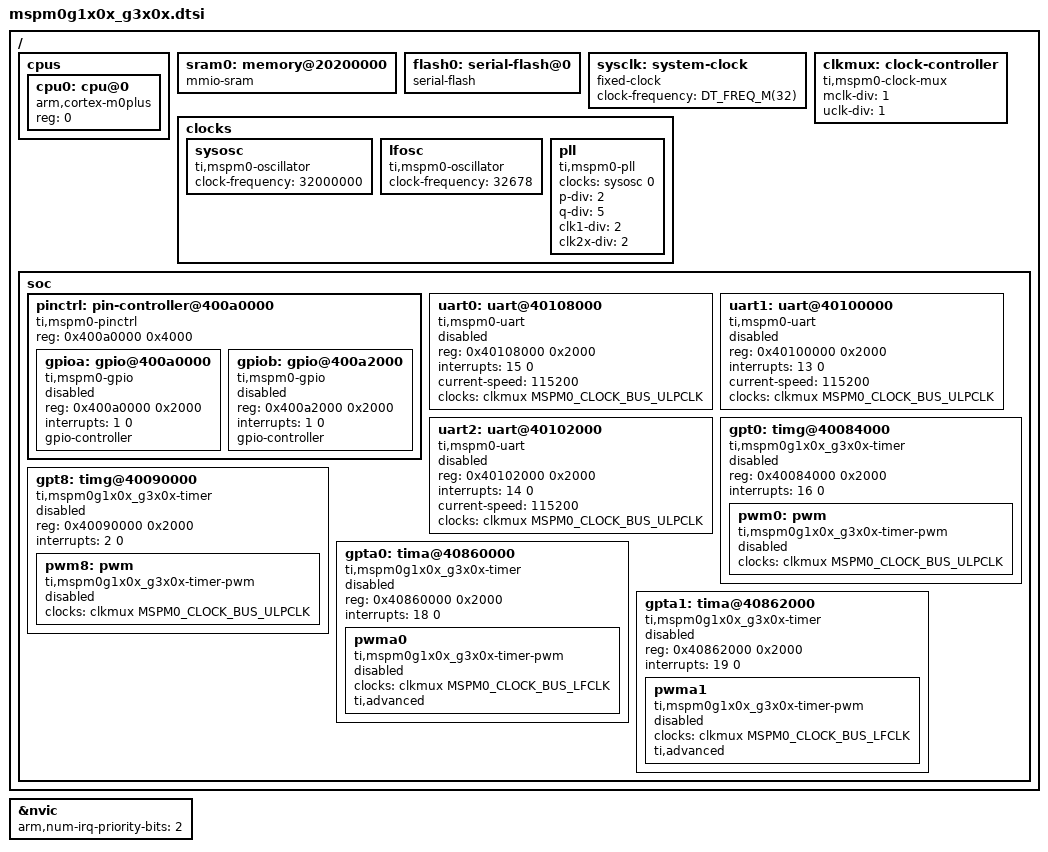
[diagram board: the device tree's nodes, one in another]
/* SPDX-License-Identifier: Apache-2.0 */

#include <arm/armv6-m.dtsi>
#include <zephyr/dt-bindings/gpio/gpio.h>
#include <zephyr/dt-bindings/i2c/i2c.h>
#include <zephyr/dt-bindings/clock/mspm0_clock.h>
#include <freq.h>

/ {
	cpus {
		#address-cells = <1>;
		#size-cells = <0>;

		cpu0: cpu@0 {
			compatible = "arm,cortex-m0plus";
			reg = <0>;
		};
	};

	sram0: memory@20200000 {
		compatible = "mmio-sram";
	};

	flash0: serial-flash@0 {
		compatible = "serial-flash";
	};

	sysclk: system-clock {
		compatible = "fixed-clock";
		clock-frequency = <DT_FREQ_M(32)>;
		#clock-cells = <0>;
	};

	clkmux: clock-controller {
		compatible = "ti,mspm0-clock-mux";
		mclk-div = <1>;
		uclk-div = <1>;
		#clock-cells = <1>;
	};

	clocks: clocks {
		sysosc: sysosc {
			compatible = "ti,mspm0-oscillator";
			clock-frequency = <32000000>;
			#clock-cells = <1>;
		};

		lfosc: lfosc {
			compatible = "ti,mspm0-oscillator";
			clock-frequency = <32678>;
			#clock-cells = <1>;
		};

		pll: pll {
			compatible = "ti,mspm0-pll";
			clocks = <&sysosc 0>;
			p-div = <2>;
			q-div = <5>;
			clk1-div = <2>;
			clk2x-div = <2>;
			#clock-cells = <0>;
			status = "okay";
		};
	};

	soc {

		pinctrl: pin-controller@400a0000{
			compatible = "ti,mspm0-pinctrl";
			#address-cells = <1>;
			#size-cells = <1>;
			reg = <0x400a0000 0x4000>;

			gpioa: gpio@400a0000 {
				compatible = "ti,mspm0-gpio";
				reg = <0x400a0000 0x2000>;
				interrupts = <1 0>;
				status = "disabled";
				gpio-controller;
				#gpio-cells = <2>;
			};

			gpiob: gpio@400a2000 {
				compatible = "ti,mspm0-gpio";
				reg = <0x400a2000 0x2000>;
				interrupts = <1 0>;
				status = "disabled";
				gpio-controller;
				#gpio-cells = <2>;
			};

		};

		uart0: uart@40108000 {
			compatible = "ti,mspm0-uart";
			reg = <0x40108000 0x2000>;
			interrupts = <15 0>;
			current-speed = <115200>;
			clocks = <&clkmux MSPM0_CLOCK_BUS_ULPCLK>;
			status = "disabled";
		};

		uart1: uart@40100000 {
			compatible = "ti,mspm0-uart";
			reg = <0x40100000 0x2000>;
			interrupts = <13 0>;
			current-speed = <115200>;
			clocks = <&clkmux MSPM0_CLOCK_BUS_ULPCLK>;
			status = "disabled";
		};

		uart2: uart@40102000 {
			compatible = "ti,mspm0-uart";
			reg = <0x40102000 0x2000>;
			interrupts = <14 0>;
			current-speed = <115200>;
			clocks = <&clkmux MSPM0_CLOCK_BUS_ULPCLK>;
			status = "disabled";
		};

		gpt0: timg@40084000 {
			compatible = "ti,mspm0g1x0x_g3x0x-timer";
			reg = <0x40084000 0x2000>;
			interrupts = <16 0>;
			status = "disabled";

			pwm0: pwm {
				compatible = "ti,mspm0g1x0x_g3x0x-timer-pwm";
				clocks = <&clkmux MSPM0_CLOCK_BUS_ULPCLK>;
				#pwm-cells = <2>;
				status = "disabled";
			};
		};

		gpt8: timg@40090000 {
			compatible = "ti,mspm0g1x0x_g3x0x-timer";
			reg = <0x40090000 0x2000>;
			interrupts = <2 0>;
			status = "disabled";

			pwm8: pwm {
				compatible = "ti,mspm0g1x0x_g3x0x-timer-pwm";
				clocks = <&clkmux MSPM0_CLOCK_BUS_ULPCLK>;
				#pwm-cells = <2>;
				status = "disabled";
			};
		};

		gpta0: tima@40860000 {
			compatible = "ti,mspm0g1x0x_g3x0x-timer";
			reg = <0x40860000 0x2000>;
			interrupts = <18 0>;
			status = "disabled";

			pwma0: pwma0 {
				compatible = "ti,mspm0g1x0x_g3x0x-timer-pwm";
				clocks = <&clkmux MSPM0_CLOCK_BUS_LFCLK>;
				#pwm-cells = <2>;
				ti,advanced;
				status = "disabled";
			};
		};

		gpta1: tima@40862000 {
			compatible = "ti,mspm0g1x0x_g3x0x-timer";
			reg = <0x40862000 0x2000>;
			interrupts = <19 0>;
			status = "disabled";

			pwma1: pwma1 {
				compatible = "ti,mspm0g1x0x_g3x0x-timer-pwm";
				clocks = <&clkmux MSPM0_CLOCK_BUS_LFCLK>;
				#pwm-cells = <2>;
				ti,advanced;
				status = "disabled";
			};
		};
	};
};

&nvic {
	arm,num-irq-priority-bits = <2>;
};
